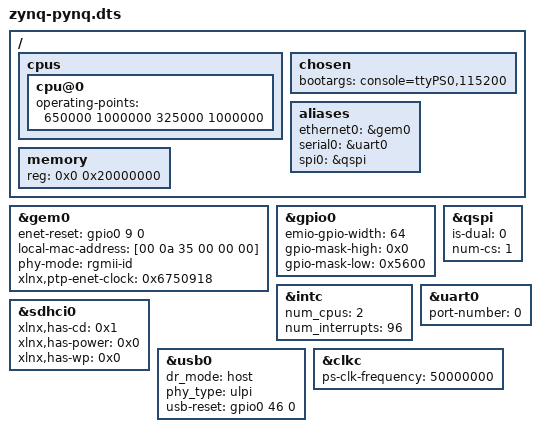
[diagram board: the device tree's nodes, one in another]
/*
 * CAUTION: This file is automatically generated by Xilinx.
 * Version:  
 * Today is: Thu Dec  8 20:46:52 2016
*/


/dts-v1/;
/include/ "zynq-7000.dtsi"

/ {
	cpus {
		cpu@0 {
			operating-points = <650000 1000000 325000 1000000>;
		};
	};
	chosen {
		bootargs = "console=ttyPS0,115200";
	};
	aliases {
		ethernet0 = &gem0;
		serial0 = &uart0;
		spi0 = &qspi;
	};
	memory {
		device_type = "memory";
		reg = <0x0 0x20000000>;
	};
};
&gem0 {
	enet-reset = <&gpio0 9 0>;
	local-mac-address = [00 0a 35 00 00 00];
	phy-mode = "rgmii-id";
	status = "okay";
	xlnx,ptp-enet-clock = <0x6750918>;
};
&gpio0 {
	emio-gpio-width = <64>;
	gpio-mask-high = <0x0>;
	gpio-mask-low = <0x5600>;
};
&intc {
	num_cpus = <2>;
	num_interrupts = <96>;
};
&qspi {
	is-dual = <0>;
	num-cs = <1>;
	status = "okay";
};
&sdhci0 {
	status = "okay";
	xlnx,has-cd = <0x1>;
	xlnx,has-power = <0x0>;
	xlnx,has-wp = <0x0>;
};
&uart0 {
	device_type = "serial";
	port-number = <0>;
	status = "okay";
};
&usb0 {
	dr_mode = "host";
	phy_type = "ulpi";
	status = "okay";
	usb-reset = <&gpio0 46 0>;
};
&clkc {
	ps-clk-frequency = <50000000>;
};
